# AT32F403Axx register map
Vendor: Keil; Series: AT32F403A; File version: 1.0
CPU: CM4 r0p1, little endian, no MPU, FPU, 4 interrupt priority bits
Registers are 32-bit, read-write, reset 0x0 unless marked. A register's access mark holds for its fields unless they carry their own. Offsets are from the block's base; [hi:lo] are bit positions.

## SPI1 — Serial peripheral interface
Base 0x40013000
Same registers: SPI2 0x40003800, SPI3 0x40003C00, SPI4 0x40004000, I2S2EXT 0x40016C00, I2S3EXT 0x40017000
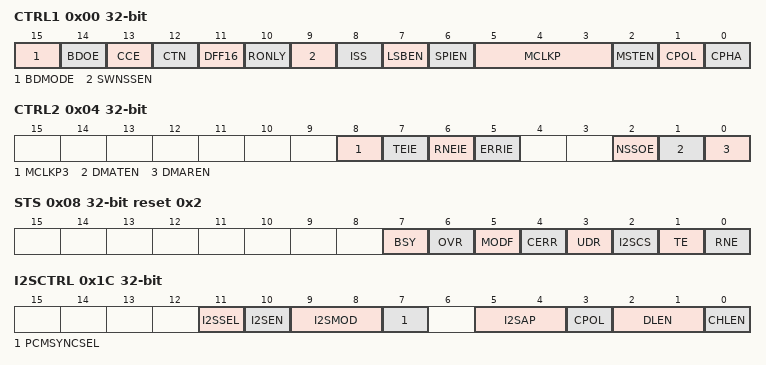
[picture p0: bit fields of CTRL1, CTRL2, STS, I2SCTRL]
0x00 CTRL1 — control register 1
  [15] BDMODE — Bidirectional data mode enable
  [14] BDOE — Output enable in bidirectional mode
  [13] CCE — Hardware CRC calculation enable
  [12] CTN — CRC transfer next
  [11] DFF16 — Data frame format
  [10] RONLY — Receive only
  [9] SWNSSEN — Software slave management
  [8] ISS — Internal slave select
  [7] LSBEN — Frame format
  [6] SPIEN — SPI enable
  [5:3] MCLKP — Baud rate control
  [2] MSTEN — Master selection
  [1] CPOL — Clock polarity
  [0] CPHA — Clock phase
0x04 CTRL2 — control register 2
  [8] MCLKP3 — Baud rate control bit3
  [7] TEIE — Tx buffer empty interrupt enable
  [6] RNEIE — RX buffer not empty interrupt enable
  [5] ERRIE — Error interrupt enable
  [2] NSSOE — SS output enable
  [1] DMATEN — Tx buffer DMA enable
  [0] DMAREN — Rx buffer DMA enable
0x08 STS reset 0x2 — status register
  [7] BSY ro — Busy flag
  [6] OVR ro — Overrun flag
  [5] MODF ro — Mode fault
  [4] CERR — CRC error flag
  [3] UDR ro — Underrun flag
  [2] I2SCS ro — Channel side
  [1] TE ro — Transmit buffer empty
  [0] RNE ro — Receive buffer not empty
0x0C DT — data register
  [15:0] DT — Data register
0x10 CPOLY reset 0x7 — CRC polynomial register
  [15:0] CPOLY
0x14 RCRC ro — RX CRC register
  [15:0] RCRC — Rx CRC register
0x18 TCRC ro — TX CRC register
  [15:0] TCRC — Tx CRC register
0x1C I2SCTRL — I2S configuration register
  [11] I2SSEL — I2S mode selection
  [10] I2SEN — I2S Enable
  [9:8] I2SMOD — I2S configuration mode
  [7] PCMSYNCSEL — PCM frame synchronization
  [5:4] I2SAP — I2S standard selection
  [3] CPOL — Steady state clock polarity
  [2:1] DLEN — Data length to be transferred
  [0] CHLEN — Channel length (number of bits per audio channel)
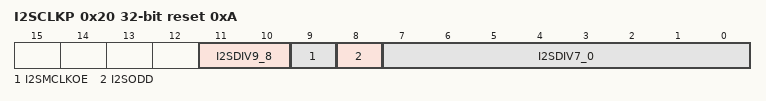
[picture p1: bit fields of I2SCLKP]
0x20 I2SCLKP reset 0xA — I2S prescaler register
  [11:10] I2SDIV9_8 — I2S Linear prescaler bit9 and bit8
  [9] I2SMCLKOE — Master clock output enable
  [8] I2SODD — Odd factor for the prescaler
  [7:0] I2SDIV7_0 — I2S Linear prescaler bit7 to bit0

## USART1 — Universal synchronous asynchronous receiver transmitter
Base 0x40013800
Same registers: USART2 0x40004400, USART3 0x40004800, USART6 0x40016000
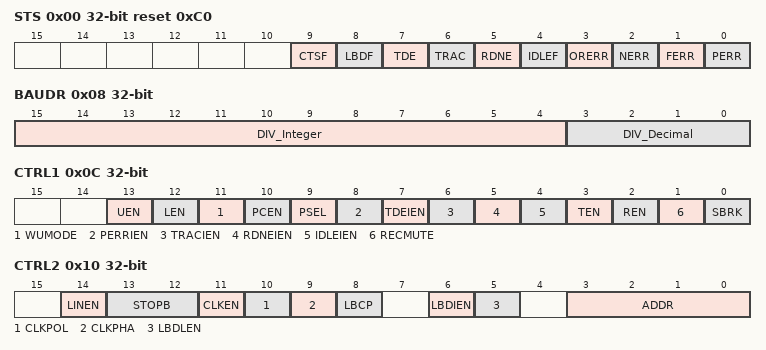
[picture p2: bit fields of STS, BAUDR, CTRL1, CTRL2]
0x00 STS reset 0xC0 — Status register
  [9] CTSF — CTS flag
  [8] LBDF — LIN break detection flag
  [7] TDE ro — Transmit data register empty
  [6] TRAC — Transmission complete
  [5] RDNE — Read data register not empty
  [4] IDLEF ro — IDLE line detected
  [3] ORERR ro — Overrun error
  [2] NERR ro — Noise error flag
  [1] FERR ro — Framing error
  [0] PERR ro — Parity error
0x04 DT — Data register
  [8:0] DT — Data value
0x08 BAUDR — Baud rate register
  [15:4] DIV_Integer — mantissa of USARTDIV
  [3:0] DIV_Decimal — fraction of USARTDIV
0x0C CTRL1 — Control register 1
  [13] UEN — USART enable
  [12] LEN — Word length
  [11] WUMODE — Wakeup method
  [10] PCEN — Parity control enable
  [9] PSEL — Parity selection
  [8] PERRIEN — PE interrupt enable
  [7] TDEIEN — TXE interrupt enable
  [6] TRACIEN — Transmission complete interrupt enable
  [5] RDNEIEN — RXNE interrupt enable
  [4] IDLEIEN — IDLE interrupt enable
  [3] TEN — Transmitter enable
  [2] REN — Receiver enable
  [1] RECMUTE — Receiver wakeup
  [0] SBRK — Send break
0x10 CTRL2 — Control register 2
  [14] LINEN — LIN mode enable
  [13:12] STOPB — STOP bits
  [11] CLKEN — Clock enable
  [10] CLKPOL — Clock polarity
  [9] CLKPHA — Clock phase
  [8] LBCP — Last bit clock pulse
  [6] LBDIEN — LIN break detection interrupt enable
  [5] LBDLEN — lin break detection length
  [3:0] ADDR — Address of the USART node
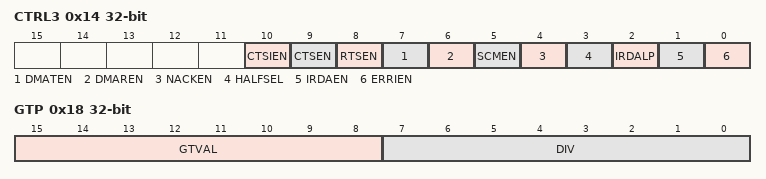
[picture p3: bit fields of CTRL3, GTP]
0x14 CTRL3 — Control register 3
  [10] CTSIEN — CTS interrupt enable
  [9] CTSEN — CTS enable
  [8] RTSEN — RTS enable
  [7] DMATEN — DMA enable transmitter
  [6] DMAREN — DMA enable receiver
  [5] SCMEN — Smartcard mode enable
  [4] NACKEN — Smartcard NACK enable
  [3] HALFSEL — Half-duplex selection
  [2] IRDALP — IrDA low-power
  [1] IRDAEN — IrDA mode enable
  [0] ERRIEN — Error interrupt enable
0x18 GTP — Guard time and prescaler register
  [15:8] GTVAL — Guard time value
  [7:0] DIV — Prescaler value
